VERSION ""

NS_ :

BS_:

BU_: Radar
VAL_TABLE_ Binary 1 "Valid" 0 "Invalid" ;

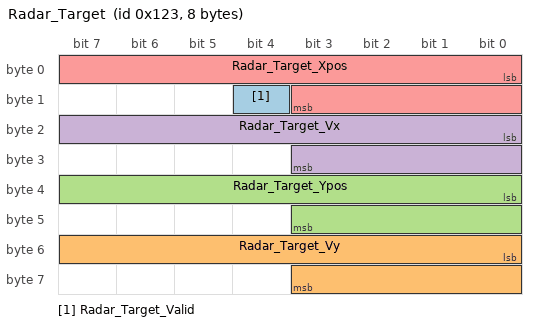
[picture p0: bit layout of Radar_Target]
BO_ 291 Radar_Target: 8 Radar
 SG_ Radar_Target_Valid : 12|1@1- (1,0) [0|0] "" Vector__XXX
 SG_ Radar_Target_Vy : 48|12@1- (0.0625,-125) [0|0] "" Vector__XXX
 SG_ Radar_Target_Ypos : 32|12@1+ (0.0625,0) [0|0] "" Vector__XXX
 SG_ Radar_Target_Vx : 16|12@1- (0.0625,-128) [0|0] "" Vector__XXX
 SG_ Radar_Target_Xpos : 0|12@1+ (0.0625,0) [0|0] "m" Vector__XXX

BA_DEF_  "BusType" STRING ;
BA_DEF_DEF_  "BusType" "CAN";
VAL_ 291 Radar_Target_Valid 1 "Valid" 0 "Invalid" ;
